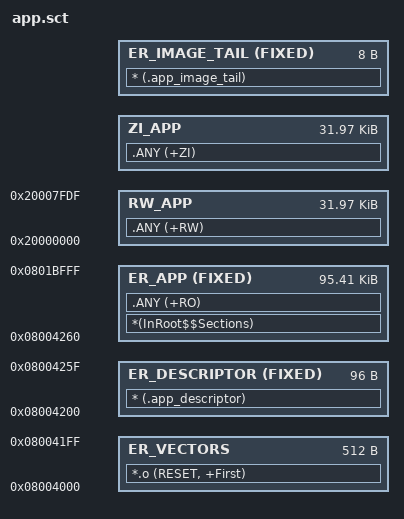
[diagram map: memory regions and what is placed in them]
; APP专用Loader布局，工程必须同时编入app_descriptor.c和显式版本/角色宏。
LR_APP 0x08004000 0x18000
{
    ER_VECTORS 0x08004000 0x200 { *.o (RESET, +First) }
    ER_DESCRIPTOR 0x08004200 FIXED 0x60 { * (.app_descriptor) }
    ER_APP 0x08004260 FIXED 0x17DA0
    {
        *(InRoot$$Sections)
        .ANY (+RO)
    }
    RW_APP 0x20000000 0x7FE0 { .ANY (+RW) }
    ZI_APP +0 0x7FE0 { .ANY (+ZI) }
    ScatterAssert(ImageLimit(ZI_APP) <= 0x20007FE0)
    ; 尾段按加载地址对齐，保证调试镜像和CAN包都由同一个合法AXF生成。
    ER_IMAGE_TAIL AlignExpr(ImageLimit(ER_APP) + ImageLength(RW_APP), 8) FIXED 0x8 { * (.app_image_tail) }
}
